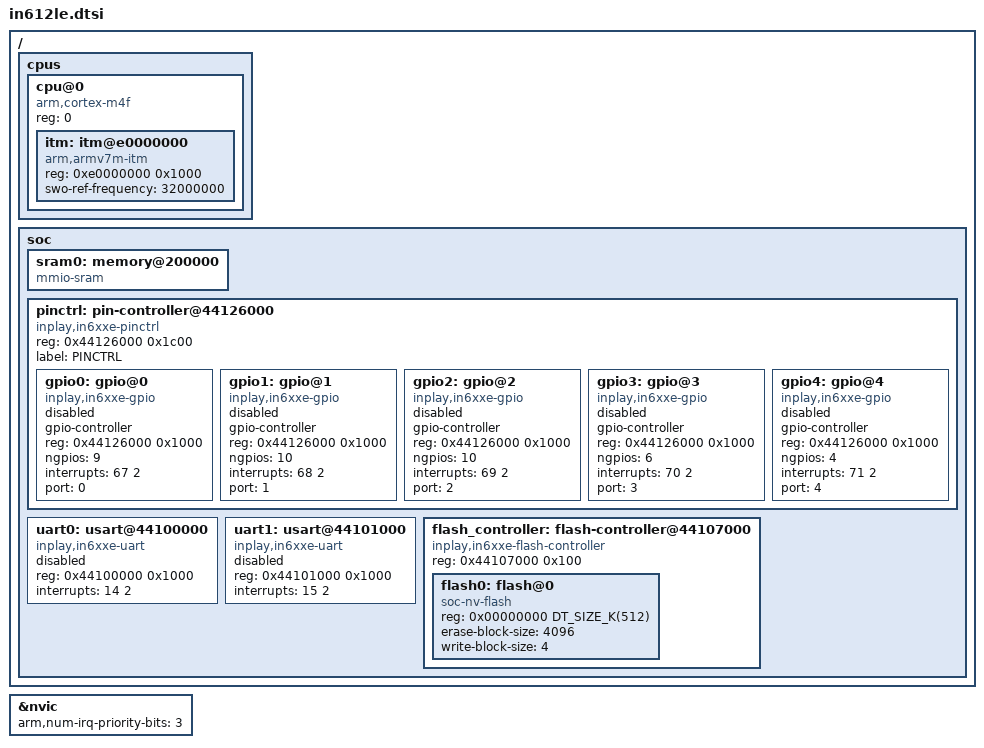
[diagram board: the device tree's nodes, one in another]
/* SPDX-License-Identifier: Apache-2.0 */
#include <mem.h>
#include <arm/armv7-m.dtsi>
#include <zephyr/dt-bindings/adc/adc.h>
#include <zephyr/dt-bindings/adc/nrf-adc.h>
#include <zephyr/dt-bindings/gpio/gpio.h>
#include <zephyr/dt-bindings/i2c/i2c.h>
//#include <zephyr/dt-bindings/pinctrl/nrf-pinctrl.h>
#include <zephyr/dt-bindings/pwm/pwm.h>

/ {

	cpus {
		#address-cells = <1>;
		#size-cells = <0>;

		cpu@0 {
			device_type = "cpu";
			compatible = "arm,cortex-m4f";
			reg = <0>;
			#address-cells = <1>;
			#size-cells = <1>;

			itm: itm@e0000000 {
				compatible = "arm,armv7m-itm";
				reg = <0xe0000000 0x1000>;
				swo-ref-frequency = <32000000>;
			};
		};
	};

	soc {

		sram0: memory@200000 {
			compatible = "mmio-sram";
		};
		pinctrl: pin-controller@44126000 {
			compatible = "inplay,in6xxe-pinctrl";
			reg = <0x44126000 0x1c00>;
			#address-cells = <1>;
			#size-cells = <1>;
			status = "okay";
			label = "PINCTRL";

			gpio0: gpio@0 {
				compatible = "inplay,in6xxe-gpio";
				gpio-controller;
				reg = <0x44126000 0x1000>;
				#gpio-cells = <2>;
				ngpios = <9>;
				interrupts = <67 2>;
				status = "disabled";
				port = <0>;
			};

			gpio1: gpio@1 {
				compatible = "inplay,in6xxe-gpio";
				gpio-controller;
				reg = <0x44126000 0x1000>;
				#gpio-cells = <2>;
				ngpios = <10>;
				interrupts = <68 2>;
				status = "disabled";
				port = <1>;
			};

			gpio2: gpio@2 {
				compatible = "inplay,in6xxe-gpio";
				gpio-controller;
				reg = <0x44126000 0x1000>;
				#gpio-cells = <2>;
				ngpios = <10>;
				interrupts = <69 2>;
				status = "disabled";
				port = <2>;
			};

			gpio3: gpio@3 {
				compatible = "inplay,in6xxe-gpio";
				gpio-controller;
				reg = <0x44126000 0x1000>;
				#gpio-cells = <2>;
				ngpios = <6>;
				interrupts = <70 2>;
				status = "disabled";
				port = <3>;
			};

			gpio4: gpio@4 {
				compatible = "inplay,in6xxe-gpio";
				gpio-controller;
				reg = <0x44126000 0x1000>;
				#gpio-cells = <2>;
				ngpios = <4>;
				interrupts = <71 2>;
				status = "disabled";
				port = <4>;
			};
		};

		uart0: usart@44100000{
			compatible = "inplay,in6xxe-uart";
			reg = <0x44100000 0x1000>;
			interrupts = <14 2>;
			status = "disabled";
		};

		uart1: usart@44101000{
			compatible = "inplay,in6xxe-uart";
			reg = <0x44101000 0x1000>;
			interrupts = <15 2>;
			status = "disabled";
		};
		flash_controller: flash-controller@44107000 {
			compatible = "inplay,in6xxe-flash-controller";
			reg = <0x44107000 0x100>;
			
			#address-cells = <1>;
			#size-cells = <1>;


			flash0: flash@0 {
				compatible = "soc-nv-flash";
				reg = <0x00000000 DT_SIZE_K(512)>;
				erase-block-size = <4096>;
				write-block-size = <4>;
			};
		};
	};
};



&nvic {
	arm,num-irq-priority-bits = <3>;
};
